# MCBSP1_DSP register map
Vendor: Texas Instruments
Peripheral module from a debugger description file (folder omap4430).
Registers are 32-bit, access per field, reset values left out (the file's numbers can be read two ways) unless marked. A register's access mark holds for its fields unless they carry their own. Offsets are as the file gives them; lines under a group give offsets from that group; [hi:lo] are bit positions; {n}, {i} and the like mark numbered series; 'fields as' and 'values as' point back to an identical list; <NAME> marks a mode.

## MCBSP1_DSP
0x00 MCBSPLP_DRR_REG ro — McBSPLP data receive register
  [31:0] DRR — Data receive register
0x08 MCBSPLP_DXR_REG wo — McBSPLP data transmit register
  [31:0] DXR — Data transmit register
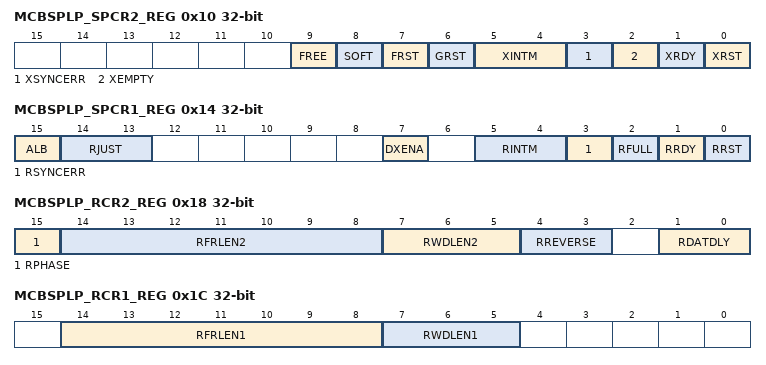
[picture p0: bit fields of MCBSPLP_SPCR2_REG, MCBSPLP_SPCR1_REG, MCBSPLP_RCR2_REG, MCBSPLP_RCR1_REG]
0x10 MCBSPLP_SPCR2_REG — McBSPLP serial port control register 2
  [9] FREE rw — Free Running Mode (When this bit is set, the module ignores the Msuspend input)
    0=Free running mode is disabled; 1=Free running mode is enabled
  [8] SOFT rw — Soft Bit
    0=SOFT mode is disabled: the module stops its activity immediately following MSuspend assertion; 1=SOFT mode is enabled: the module freezes its state after completion of the current operation when MSuspend is asserted
  [7] FRST rw — Frame-Sync Generator Reset
    0=Frame-sync logic is reset. Frame-sync signal FSG is not generated by the sample-rate generator; 1=Frame-sync signal FSG is generated after (FPER+1) number of CLKG clocks; that is, all frame counters are loaded with their programmed values
  [6] GRST rw — Sample-Rate Generator Reset
    0=SRG is reset; 1=SRG is pulled out of reset. CLKG is driven as per programmed value in SRG registers (SRGR[1,2])
  [5:4] XINTM rw — Transmit Interrupt Mode (legacy)
    0=XINT is driven by XRDY; 1=XINT generated by end-of-frame; 2=XINT generated by a new frame synchronization; 3=XINT generated by XSYNCERR
  [3] XSYNCERR rw — Transmit Synchronization Error (writing 0 to this bit clear the legacy transmit interrupt if asserted due to XSYNCERR condition)
    0=No synchronization error; 1=Synchronization error detected by McBSP
  [2] XEMPTY ro — Transmit Shift Register XSR Empty
    0=XEMPTY_0_r (XSR is empty); 1=XEMPTY_1_r (XSR is not empty)
  [1] XRDY ro — Transmitter ready
    0=XRDY_0_r (Transmitter is not ready.); 1=XRDY_1_r (Transmitter is ready for new data in DXR)
  [0] XRST rw — Transmitter reset. This resets and enables the transmitter.
    0=The serial port transmitter is disabled and in reset state; 1=The serial port transmitter is enabled
0x14 MCBSPLP_SPCR1_REG — McBSPLP serial port control register 1
  [15] ALB rw — Analog Loopback Mode
    0=Analog loopback mode disabled; 1=Analog loopback mode enabled
  [14:13] RJUST rw — Receive Sign-Extension and Justification Mode
    0=Right-justify and zero-fill MSBs in DRR; 1=Right-justify and sign-extend MSBs in DRR; 2=Left-justify and zero-fill LSBs in DRR
  [7] DXENA rw — DX Enabler
    0=DX enabler is off; 1=DX enabler is on
  [5:4] RINTM rw — Receive Interrupt Mode (legacy)
    0=RINT driven by RRDY (that is, end of word) and end of frame in A-bis mode; 1=RINT generated by end-of-block or end-of-frame in multichannel operation; 2=RINT generated by a new frame synchronization; 3=RINT generated by RSYNCERR
  [3] RSYNCERR rw — Receive Synchronization Error (writing 0 to this bit clear the legacy receive interrupt if asserted due to RSYNCERR condition)
    values as MCBSPLP_SPCR2_REG.XSYNCERR
  [2] RFULL ro — Receive Shift Register (RSR]) Full
    0=RFULL_0_r (DRR is not read, RB is full and RSR is also full with new word); 1=RFULL_1_r (RB is not in overrun condition)
  [1] RRDY ro — Receiver Ready
    0=RRDY_0_r (Receiver is not ready); 1=RRDY_1_r (Receiver is ready with data to be read from DRR)
  [0] RRST rw — Receiver reset. This resets and enables the receiver.
    0=The serial port receiver is disabled and in reset state; 1=The serial port receiver is enabled
0x18 MCBSPLP_RCR2_REG — McBSPLP receive control register 2
  [15] RPHASE rw — Receive Phases
    0=Single-phase frame; 1=Dual-phase frame
  [14:8] RFRLEN2 rw — Receive Frame Length 2 Single-phase frame selected: RFRLEN2=don't care Dual-phase frame selected: RFRLEN2=000 0000 - 1 word per second phase (other values are reserved)
  [7:5] RWDLEN2 rw — Receive Word Length 2
    0=8 bits; 1=12 bits; 2=16 bits; 3=20 bits; 4=24 bits; 5=32 bits
  [4:3] RREVERSE rw — Receive reverse mode.
    0=Data transfer starts with MSB first; 1=Data transfer starts with LSB first
  [1:0] RDATDLY rw — Receive Data Delay
    0=0-bit data delay; 1=1-bit data delay; 2=2-bit data delay
0x1C MCBSPLP_RCR1_REG — McBSPLP receive control register 1
  [14:8] RFRLEN1 rw — Receive Frame Length 1 Single-phase frame selected: RFRLEN1=000 0000 - 1 word per frame RFRLEN1=000 0001 - 2 words per frame RFRLEN1=111 1111 - 128 words per frame Dual-phase frame selected: RFRLEN1=000 0000 - 1 word per phase (other values are reserved)
  [7:5] RWDLEN1 rw — Receive Word Length 1
    values as MCBSPLP_RCR2_REG.RWDLEN2
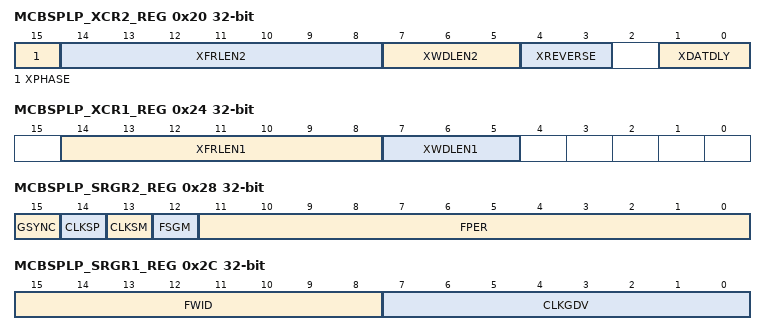
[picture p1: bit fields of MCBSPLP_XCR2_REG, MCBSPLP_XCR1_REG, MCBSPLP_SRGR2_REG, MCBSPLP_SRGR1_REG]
0x20 MCBSPLP_XCR2_REG — McBSPLP transmit control register 2
  [15] XPHASE rw — Transmit Phases
    0=Single-phase frame; 1=Dual-phase frame
  [14:8] XFRLEN2 rw — Transmit Frame Length 2 Single-phase frame selected: XFRLEN2=don't care Dual-phase frame selected: XFRLEN2=000 0000 - 1 word per second phase (other values are reserved)
  [7:5] XWDLEN2 rw — Transmit Word Length 2
    values as MCBSPLP_RCR2_REG.RWDLEN2
  [4:3] XREVERSE rw — Transmit reverse mode.
    values as MCBSPLP_RCR2_REG.RREVERSE
  [1:0] XDATDLY rw — Transmit Data Delay
    0=0-bit data delay; 1=1-bit data delay; 2=2-bit data delay
0x24 MCBSPLP_XCR1_REG — McBSPLP transmit control register 1
  [14:8] XFRLEN1 rw — Transmit Frame Length 1 Single-phase frame selected: XFRLEN1=000 0000 - 1 word per frame XFRLEN1=000 0001 - 2 words per frame XFRLEN1=111 1111 - 128 words per frame Dual-phase frame selected: XFRLEN1=000 0000 - 1 word per phase (other values are reserved)
  [7:5] XWDLEN1 rw — Transmit Word Length 1
    values as MCBSPLP_RCR2_REG.RWDLEN2
0x28 MCBSPLP_SRGR2_REG — McBSPLP sample rate generator register 2
  [15] GSYNC rw
    0=The SRG clock (CLKG) is free running; 1=The SRG clock (CLKG) is running. But CLKG is resynchronized and frame-sync signal (FSG) is generated only after detecting the receive frame-sync signal (FSR). Also, frame period, FPER, is a don't care because the period is dictated by the external frame-sync pulse.
  [14] CLKSP rw — CLKS Polarity Clock Edge Select Only used when the external clock CLKS drives the SRG clock (CLKSM=0).
    0=Rising edge of CLKG and FSG; 1=Falling edge of CLKG and FSG
  [13] CLKSM rw — McBSPLP Sample Rate Generator Clock Mode
    0=SCLKME=0: SRG clock derived from the CLKS pin. SCLKME=1: SRG clock derived from the CLKRI pin.; 1=SCLKME=0: SRG clock derived from the CPU clock. SCLKME=1: SRG clock derived from the CLKXI clock.
  [12] FSGM rw — Sample Rate Generator Transmit Frame-Synchronization Mode Used when FSXM=1 in the PCR.
    0=Transmit frame-sync signal (FSX) is generated when transmit buffer is not empty When FSGM=0, FPER and FWID are used to determine the frame-sync period and width (external FSX is gated by the buffer empty condition); 1=Transmit frame-sync signal driven by the SRG frame-sync signal, FSG
  [11:0] FPER rw — Frame Period. This field plus 1 determines when the next frame-sync signal becomes active. Range: 1 to 4096 CLKG periods
0x2C MCBSPLP_SRGR1_REG — McBSPLP sample rate generator register 1
  [15:8] FWID rw — Frame Width. This field plus 1 determines the width of the frame-sync pulse, FSG, during its active period. Range: 1 to 256 CLKG periods.
  [7:0] CLKGDV rw — Sample Rate Generator Clock Divider This value is used as the divide-down number to generate the required SRG clock frequency. Default value is 1.
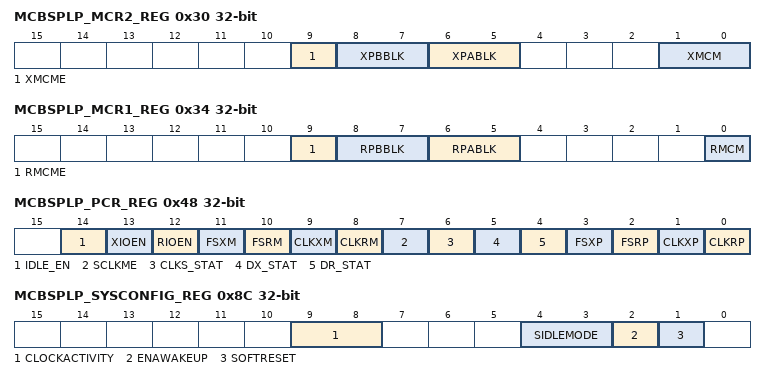
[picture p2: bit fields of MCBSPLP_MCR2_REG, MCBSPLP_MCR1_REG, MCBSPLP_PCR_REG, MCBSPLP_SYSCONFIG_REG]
0x30 MCBSPLP_MCR2_REG — McBSPLP multi channel register 2
  [9] XMCME rw
    0=2-partition mode: Only partitions A and B are used. You can control up to 32 channels in the transmit multichannel selection mode selected with the XMCM bits. If XMCM = 01b or 10b, assign 16 channels to partition A with the XPABLK bits. Assign 16 channels to partition B with the XPBBLK bits. If XMCM = 11b (for symmetric transmission and reception), assign 16 channels to receive partition A with the RPABLK bits. Assign 16 channels to receive partition B with the RPBBLK bits. You control the channels with the appropriate transmit channel enable registers: XCERA: Channels in partition A XCERB: Channels in partition B; 1=8-partition mode: All partitions (A through H) are used. You can control up to 128 channels in the transmit multichannel selection mode selected with the XMCM bits. You control the channels with the appropriate transmit channel enable registers: XCERA: Channels 0 through 15 XCERB: Channels 16 through 31 XCERC: Channels 32 through 47 XCERD: Channels 48 through 63 XCERE: Channels 64 through 79 XCERF: Channels 80 through 95 XCERG: Channels 96 through 111 XCERH: Channels 112 through 127
  [8:7] XPBBLK rw — Transmit Partition B Block (legacy)
    0=Block 1. Channel 16 to channel 31; 1=Block 3. Channel 48 to channel 63; 2=Block 5. Channel 80 to channel 95; 3=Block 7. Channel 112 to channel 127
  [6:5] XPABLK rw — Transmit Partition A Block (legacy)
    0=Block 0. Channel 0 to channel 15; 1=Block 2. Channel 32 to channel 47; 2=Block 4. Channel 64 to channel 79; 3=Block 6. Channel 96 to channel 111
  [1:0] XMCM rw — Transmit Multichannel Selection Enable
    0=All channels enabled without masking (DX is always driven during transmission of data); 1=All channels disabled and therefore masked by default. Required channels are selected by enabling XP(A/B)BLK and XCER(A/B) appropriately. Also, these selected channels are not masked and therefore DX is always driven.; 2=All channels enabled, but masked. Selected channels enabled via XP(A/B)BLK and XCER(A/B) are unmasked.; 3=All channels disabled and therefore masked by default. Required channels are selected by enabling RP(A/B)BLK and RCER(A/B) appropriately. Selected channels can be unmasked by RP(A/B)BLK and XCER(A/B). This mode is used for symetric transmit and receive operation.
0x34 MCBSPLP_MCR1_REG — McBSPLP multi channel register 1
  [9] RMCME rw — (legacy)
    0=2-partition mode. Only partitions A and B are used. You can control up to 32 channels in the receive multichannel selection mode (RMCM = 1). Assign 16 channels to partition A with the RPABLK bits. Assign 16 channels to partition B with the RPBBLK bits. You control the channels with the apropriate receive channel enable registers: RCERA: Channels in partition A RCERB: Channels in partition B; 1=8-partition mode: All partitions (A through H) are used. You can control up to 128 channels in the receive multichannel selection mode. You control the channels with the appropriate receive channel enable registers: RCERA: Channels 0 through 15 RCERB: Channels 16 through 31 RCERC: Channels 32 through 47 RCERD: Channels 48 through 63 RCERE: Channels 64 through 79 RCERF: Channels 80 through 95 RCERG: Channels 96 through 111 RCERH: Channels 112 through 127
  [8:7] RPBBLK rw — Receive Partition B Block (legacy)
    values as MCBSPLP_MCR2_REG.XPBBLK
  [6:5] RPABLK rw — Receive Partition A Block (legacy)
    values as MCBSPLP_MCR2_REG.XPABLK
  [0] RMCM rw — Receive Multichannel Selection Enable
    0=All 128 channels; 1=All channels disabled by default. Required channels are selected by enabling RP(A/B)BLK and RCER(A/B) appropriately
0x38 MCBSPLP_RCERA_REG — McBSPLP receive channel enable register partition A
  [15:0] RCERA rw — Receive Channel Enable RCERA n=0 Disables reception of n-th channel in an even-numbered block in partition A RCERA n=1 Enables reception of n-th channel in an even-numbered block in partition A
0x3C MCBSPLP_RCERB_REG — McBSPLP receive channel enable register partition B
  [15:0] RCERB rw — Receive Channel Enable RCERB n=0 Disables reception of n-th channel in a even-numbered block in partition B RCERB n=1 Enables reception of n-th channel in a even-numbered block in partition B
0x40 MCBSPLP_XCERA_REG — McBSPLP transmit channel enable register partition A
  [15:0] XCERA rw — Transmit Channel Enable XCERA n=0 Disables transmission of n-th channel in an event-numbered block in partition A XCERA n=1 Enables transmission of n-th channel in an event-numbered block in partition A
0x44 MCBSPLP_XCERB_REG — McBSPLP transmit channel enable register partition B
  [15:0] XCERB rw — Transmit Channel Enable XCERB n=0 Disables transmission of n-th channel in an even-numbered block in partition B XCERB n=1 Enables transmission of n-th channel in an even-numbered block in partition B
0x48 MCBSPLP_PCR_REG — McBSPLP pin control register
  [14] IDLE_EN rw — Idle enable. This bit allows stopping all the clocks in the MCBSPLP. (legacy)
    0=The McBSP is running; 1=The clocks in the McBSP are shut off when both IDLE_EN=1 and peripheral domain is in idle mode
  [13] XIOEN rw — Transmit General Purpose I/O Mode only when XRST=0 in SPCR[1,2] (legacy)
    0=DX, FSX and CLKX are configured as serial port pins and do not function as general-purpose I/Os; 1=DX pin is a general purpose output. FSX and CLKX are general purpose I/Os. These serial port pins do not perform serial port operation.
  [12] RIOEN rw — Receive General Purpose I/O Mode when RRST=0 in SPCR[1,2] (legacy)
    0=DR, FSR, CLKR and CLKS are configured as serial port pins and do not function as general-purpose I/Os; 1=DR and CLKS pins are general purpose inputs; FSR and CLKR are general purpose I/Os. These serial port pins do not perform serial port operation. The CLKS pin is affected by a combination of RRST and RIOEN signals of the receiver.
  [11] FSXM rw — Transmit Frame-Synchronization Mode
    0=Frame-sync signal derived from an external source; 1=Frame synchronization is determined by the SRG frame-sync mode bit FSGM in SRGR2
  [10] FSRM rw — Receive Frame-Synchronization Mode
    0=Frame-sync pulses generated by an external device. FSR is an input pin.; 1=Frame synchronization generated internally by SRG. FSR is an output pin except when GSYNC=1 in SRGR.
  [9] CLKXM rw — Transmitter Clock Mode
    0=Transmitter clock is driven by an external clock with CLKX as an input pin; 1=CLKX is an output pin and is driven by the internal sample rate generator
  [8] CLKRM rw — Receiver Clock Mode
    0=Case 1: Digital loopback mode not set (DLB=0) in SPCR1: Receive clock (CLKR) is an input driven by an externaal clock. Case 2: Digital loopback mode set (DLB=1) in SPCR1: Receive clock (not the CLKR pin) is driven by transmit clock (CLKX) which is based on the CLKXM bit in the PCR. CLKR pin is in high-impedance.; 1=Case 1: Digital loopback mode not set (DLB=0) in SPCR1: CLKR is an output pin and is driven by the internal SRG. Case 2: Digital loopback mode set (DLB=1) in SPCR1: CLKR is an output pin and is driven by the transmit clock. The transmit clock is derived based on the CLKRM bit in the PCR.
  [7] SCLKME rw — The frequency of CLKG is: CLKG frequency = (Input clock frequency) / (CLKGDV + 1) SCLKME is used in conjunction with the CLKSM bit to select the input clock:
    0=CLKSM = 0: Signal on CLKS pin CLKSM = 1: CPU clock; 1=CLKSM = 0: Signal on CLKR pin CLKSM = 1: Signal on CLKX pin
  [6] CLKS_STAT ro — CLKS pin status. Reflects value on CLKS pin when selected as a general purpose input. (legacy)
    0=CLKS_STAT_0_r (The signal on the CLKS pin is low); 1=CLKS_STAT_1_r (The signal on the CLKS pin is high)
  [5] DX_STAT rw — DX pin status. Reflects value driven on to DX pin when selected as a general purpose output. (legacy)
    0=Drive the signal on the DX pin low; 1=Drive the signal on the DX pin high
  [4] DR_STAT ro — DR pin status. Reflects value on DR pin when selected as a general purpose input. (legacy)
    0=DR_STAT_0_r (The signal on DR pin is low); 1=DR_STAT_1_r (The signal on DR pin is high)
  [3] FSXP rw — Transmit Frame-Synchronization Polarity
    0=Frame-sync pulse FSX is active high; 1=Frame-sync pulse FSX is active low
  [2] FSRP rw — Receive Frame-Synchronization Polarity
    0=Frame-sync pulse FSR is active high; 1=Frame-sync pulse FSR is active low
  [1] CLKXP rw — Transmit Clock Polarity
    0=Transmit data driven on rising edge of CLKX; 1=Transmit data driven on falling edge of CLKX
  [0] CLKRP rw — Receive Clock Polarity
    0=Receive data sampled on falling edge of CLKR; 1=Receive data sampled on rising edge of CLKR
0x4C MCBSPLP_RCERC_REG — McBSPLP receive channel enable register partition C
  [15:0] RCERC rw — Receive Channel Enable RCERC n=0 Disables reception of n-th channel in an even-numbered block in partition C RCERC n=1 Enables reception of n-th channel in an even-numbered block in partition C
0x50 MCBSPLP_RCERD_REG — McBSPLP receive channel enable register partition D
  [15:0] RCERD rw — Receive Channel Enable RCERD n=0 Disables reception of n-th channel in an even-numbered block in partition D RCERD n=1 Enables reception of n-th channel in an even-numbered block in partition D
0x54 MCBSPLP_XCERC_REG — McBSPLP transmit channel enable register partition C
  [15:0] XCERC rw — Transmit Channel Enable XCERC n=0 Disables transmission of n-th channel in an event-numbered block in partition C XCERC n=1 Enables transmission of n-th channel in an event-numbered block in partition C
0x58 MCBSPLP_XCERD_REG — McBSPLP transmit channel enable register partition D
  [15:0] XCERD rw — Transmit Channel Enable XCERD n=0 Disables transmission of n-th channel in an even-numbered block in partition D XCERD n=1 Enables transmission of n-th channel in an even-numbered block in partition D
0x5C MCBSPLP_RCERE_REG — McBSPLP receive channel enable register partition E
  [15:0] RCERE rw — Receive Channel Enable RCERE n=0 Disables reception of n-th channel in an even-numbered block in partition E RCERE n=1 Enables reception of n-th channel in an even-numbered block in partition E
0x60 MCBSPLP_RCERF_REG — McBSPLP receive channel enable register partition F
  [15:0] RCERF rw — Receive Channel Enable RCERF n=0 Disables reception of n-th channel in an even-numbered block in partition F RCERF n=1 Enables reception of n-th channel in an even-numbered block in partition F
0x64 MCBSPLP_XCERE_REG — McBSPLP transmit channel enable register partition E
  [15:0] XCERE rw — Transmit Channel Enable XCERE n=0 Disables transmission of n-th channel in an event-numbered block in partition E XCERE n=1 Enables transmission of n-th channel in an event-numbered block in partition E
0x68 MCBSPLP_XCERF_REG — McBSPLP transmit channel enable register partition F
  [15:0] XCERF rw — Transmit Channel Enable XCERF n=0 Disables transmission of n-th channel in an even-numbered block in partition F XCERF n=1 Enables transmission of n-th channel in an even-numbered block in partition F
0x6C MCBSPLP_RCERG_REG — McBSPLP receive channel enable register partition G
  [15:0] RCERG rw — Receive Channel Enable RCERG n=0 Disables reception of n-th channel in an even-numbered block in partition G RCERG n=1 Enables reception of n-th channel in an even-numbered block in partition G
0x70 MCBSPLP_RCERH_REG — McBSPLP receive channel enable register partition H
  [15:0] RCERH rw — Receive Channel Enable RCERH n=0 Disables reception of n-th channel in an even-numbered block in partition H RCERH n=1 Enables reception of n-th channel in an even-numbered block in partition H
0x74 MCBSPLP_XCERG_REG — McBSPLP transmit channel enable register partition G
  [15:0] XCERG rw — Transmit Channel Enable XCERG n=0 Disables transmission of n-th channel in an event-numbered block in partition G XCERG n=1 Enables transmission of n-th channel in an event-numbered block in partition G
0x78 MCBSPLP_XCERH_REG — McBSPLP transmit channel enable register partition H
  [15:0] XCERH rw — Transmit Channel Enable XCERH n=0 Disables transmission of n-th channel in an even-numbered block in partition H XCERH n=1 Enables transmission of n-th channel in an even-numbered block in partition H
0x7C MCBSPLP_REV_REG ro — MCBSPLP Revision number register
  [7:0] REV — Revision number
0x80 MCBSPLP_RINTCLR_REG rw — McBSPLP receive interrupt clear
  [31:0] RINTCLR — Read from this register will clear the IRQ generated by receive end-of-frame indication or MCBSPLP.FSR detection. Write to this register has no effect. (legacy)
0x84 MCBSPLP_XINTCLR_REG rw — McBSPLP transmit interrupt clear (legacy)
  [31:0] XINTCLR — Read from this register will clear the IRQ generated by transmit end-of-frame indication or MCBSPLP.FSX detection. Write to this register has no effect.
0x88 MCBSPLP_ROVFLCLR_REG rw — McBSPLP receive overflow interrupt clear
  [31:0] ROVFLCLR — Read from this register will clear the IRQ generated by the receive overflow condition. Write to this register has no effect.
0x8C MCBSPLP_SYSCONFIG_REG — McBSPLP System Configuration register
  [9:8] CLOCKACTIVITY rw
    0=The MCBSPi_ICLK clock can be switched off. The PRCM functional clock can be switched off.; 1=The MCBSPi_ICLK clock must be maintained during wakeup. The PRCM functional clock can be switched off.; 2=The MCBSPi_ICLK clock can be switched off. The PRCM functional clock must be maintained during wakeup.; 3=The MCBSPi_ICLK clock must be maintained during wakeup. The PRCM functional clock must be maintained during wakeup
  [4:3] SIDLEMODE rw — Slave interface power management, req/ack control:
    0=Force-idle. An idle request is acknowledged unconditionally.; 1=No-idle. An idle request is never acknowledged.; 2=Smart-idle. Acknowledgement to an idle request is given based on the internal activity of the module
  [2] ENAWAKEUP rw — WakeUp feature control:
    0=WakeUp is disabled; 1=WakeUp capability is enabled
  [1] SOFTRESET rw — McBSPLP global software reset
    0=NO soft reset; 1=Soft reset triggered
0x90 MCBSPLP_THRSH2_REG — McBSPLP transmit buffer threshold (DMA or IRQ trigger)
  [6:0] XTHRESHOLD rw — Transmit buffer threshold value. The DMA request (if enabled) of interrupt assertion (if enabled) will be triggered if the number of free locations inside transmit buffer are above or equal to the XTHRESHOLD value + 1. Also, this value (XTHRESHOLD value + 1) indicates the number of words transferred during a transmit data DMA request, if transmit DMA is enabled
0x94 MCBSPLP_THRSH1_REG — McBSPLP receive buffer threshold (DMA or IRQ trigger)
  [6:0] RTHRESHOLD rw — Receive buffer threshold value. The DMA request (if enabled) of interrupt assertion (if enabled) will be triggered if the number of occupied locations inside receive buffer are above or equal to the RTHRESHOLD value + 1. Also, this value (RTHRESHOLD value + 1) indicates the number of words transferred during a receive data DMA request, if receive DMA is enabled.
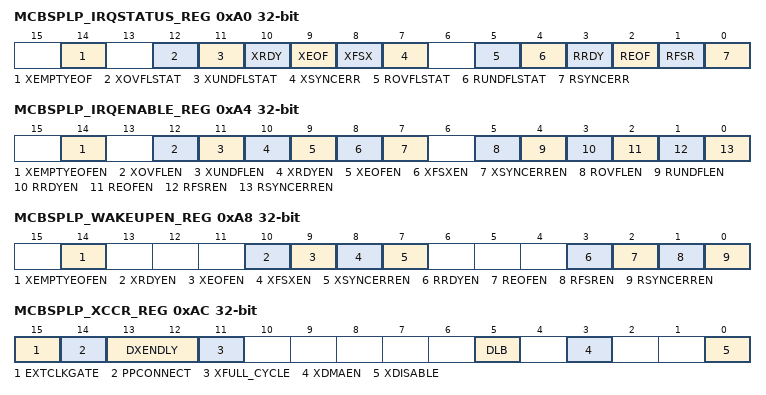
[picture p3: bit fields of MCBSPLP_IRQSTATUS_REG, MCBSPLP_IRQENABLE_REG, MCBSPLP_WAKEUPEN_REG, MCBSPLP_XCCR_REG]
0xA0 MCBSPLP_IRQSTATUS_REG — McBSPLP Interrupt Status register (interconnect compliant IRQ line)
  [14] XEMPTYEOF rw — Transmit Buffer Empty at end of frame (XEMPTYEOF is set to 1 when a complete frame was transmitted and the transmit buffer is empty).
    0=XEMPTYEOF is NOT set to when a complete frame was transmitted and the transmit buffer is empty; 1=XEMPTYEOF is set to 1 when a complete frame was transmitted and the transmit buffer is empty. Writing 1 to this bit clears the bit.
  [12] XOVFLSTAT rw — Transmit Buffer Overflow (XOVFLSTAT bit is set to 1 when transmit buffer overflow; the data which is written while overflow condition is discarded). Writing 1 to this bit clears the bit.
    0=Transmit buffer NOT overflow; 1=Transmit buffer overflow; Writing 1 to this bit clears the bit
  [11] XUNDFLSTAT rw — Transmit Buffer Underflow (XUNDFLSTAT bit is set to 1 when the transmit data buffer is empty new data is required to be transmitted). Writing 1 to this bit clears the bit.
    0=the transmit data buffer is NOT empty new data is required to be transmitted; 1=the transmit data buffer is empty new data is required to be transmitted. Writing 1 to this bit clears the bit.
  [10] XRDY rw — Transmit Buffer Threshold Reached (XRDY bit is set to 1 when the transmit buffer free locations are equal or above the THRSH2_REG value). Writing 1 to this bit clears the bit.
    0=Transmit buffer occupied locations are below the THRSH2_REG value); 1=Transmit buffer occupied locations are equal or above the THRSH2_REG value). Writing 1 to this bit clears the bit.
  [9] XEOF rw — Transmit End Of Frame (XEOF is set to 1 when a complete frame was transmitted). Writing 1 to this bit clears the bit.
    0=complete frame was NOT transmitted; 1=complete frame was transmitted; Writing 1 to this bit clears the bit
  [8] XFSX rw — Transmit Frame Synchronization (XFSX bit is set to 1 when a new transmit frame synchronization is asserted). Writing 1 to this bit clears the bit.
    0=new transmit frame synchronization is NOT asserted; 1=new transmit frame synchronization is asserted; Writing 1 to this bit clears the bit
  [7] XSYNCERR rw — Transmit Frame Synchronization Error (XSYNCERR is set to 1 when a transmit frame-sync error is detected). Writing 1 to this bit clears the bit.
    0=Transmit frame-sync error is NOT detected; 1=Transmit frame-sync error is detected. Writing 1 to this bit clears the bit.
  [5] ROVFLSTAT rw — Receive Buffer Overflow (ROVFLSTAT bit is set to 1 when receive buffer overflow; the data which is written while overflow condition is discarded). Writing 1 to this bit clears the bit.
    0=receive buffer NOT overflow; 1=receive buffer overflow; Writing 1 to this bit clears the bit
  [4] RUNDFLSTAT rw — Receive Buffer Underflow (RUNDFLSTAT bit is set to 1 when read operation is performed to the receive data register while receive buffer is empty; data read while underflow condition is undefined). Writing 1 to this bit clears the bit.
    0=read operation is performed to the receive data register while receive buffer is NOT empty; 1=read operation is performed to the receive data register while receive buffer is empty; Writing 1 to this bit clears the bit
  [3] RRDY rw — Receive Buffer Threshold Reached (RRDY bit is set to 1 when the receive buffer occupied locations are equal or above the THRSH1_REG value). Writing 1 to this bit clears the bit.
    0=receive buffer occupied locations are below the THRSH1_REG value); 1=receive buffer occupied locations are equal or above the THRSH1_REG value). Writing 1 to this bit clears the bit.
  [2] REOF rw — Receive End Of Frame (REOF is set to 1 when a complete frame was received). Writing 1 to this bit clears the bit.
    0=complete frame was NOT received; 1=complete frame was received; Writing 1 to this bit clears the bit
  [1] RFSR rw — Receive Frame Synchronization (RFSR bit is set to 1 when a new receive frame synchronization is asserted). Writing 1 to this bit clears the bit.
    0=new receive frame synchronization is NOT asserted; 1=new receive frame synchronization is asserted; Writing 1 to this bit clears the bit
  [0] RSYNCERR rw — Receive Frame Synchronization Error (RSYNCERR is set to 1 when a receive frame-sync error is detected). Writing 1 to this bit clears the bit.
    0=Receive frame-synchronization error is NOT detected; 1=Receive frame-synchronization error is detected. Writing 1 to this bit clears the bit.
0xA4 MCBSPLP_IRQENABLE_REG — McBSPLP Interrupt Enable register (interconnect compliant IRQ line)
  [14] XEMPTYEOFEN rw — Transmit buffer empty at end of frame enable bit.
    0=Transmit Buffer Empty at End Of Frame NOT enabled; 1=Transmit Buffer Empty at End Of Frame enabled
  [12] XOVFLEN rw — Transmit Buffer Overflow enable bit.
    0=Transmit Buffer Overflow NOT enabled; 1=Transmit Buffer Overflow enabled
  [11] XUNDFLEN rw — Transmit Buffer Underflow enable bit.
    0=Transmit Buffer Underflow NOT enabled; 1=Transmit Buffer Underflow enabled
  [10] XRDYEN rw — Transmit Buffer Threshold Reached enable bit.
    0=Transmit Buffer Threshold Reached NOT enabled; 1=Transmit Buffer Threshold Reached enabled
  [9] XEOFEN rw — Transmit End Of Frame enable bit.
    0=Transmit End Of Frame NOT enabled; 1=Transmit End Of Frame enabled
  [8] XFSXEN rw — Transmit Frame Synchronization enable bit.
    0=Transmit Frame Synchronization NOT enabled; 1=Transmit Frame Synchronization enabled
  [7] XSYNCERREN rw — Transmit Frame Synchronization Error enable bit.
    0=Transmit Frame Synchronization Error NOT enabled; 1=Transmit Frame Synchronization Error enabled
  [5] ROVFLEN rw — Receive Buffer Overflow enable bit.
    0=Receive Buffer Overflow NOT enabled; 1=Receive Buffer Overflow enabled
  [4] RUNDFLEN rw — Receive Buffer Underflow enable bit.
    0=Receive Buffer Underflow NOT enabled; 1=Receive Buffer Underflow enabled
  [3] RRDYEN rw — Receive Buffer Threshold enable bit.
    0=Receive Buffer Threshold NOT enabled; 1=Receive Buffer Threshold enabled
  [2] REOFEN rw — Receive End Of Frame enable bit.
    0=Receive End Of Frame NOT enabled; 1=Receive End Of Frame enabled
  [1] RFSREN rw — Receive Frame Synchronization enable bit. RW
    0=Receive Frame Synchronization NOT enabled; 1=Receive Frame Synchronization enabled
  [0] RSYNCERREN rw — Receive Frame Synchronization Error enable bit.
    0=Receive Frame Synchronization Error NOT enabled; 1=Receive Frame Synchronization Error enabled
0xA8 MCBSPLP_WAKEUPEN_REG — McBSPLP Wakeup Enable register
  [14] XEMPTYEOFEN rw — Transmit Buffer Empty at End Of Frame enable bit.
    0=Transmit Buffer Empty at End Of Frame WK enable is NOT active; 1=Transmit Buffer Empty at End Of Frame WK enable is active
  [10] XRDYEN rw — Transmit Buffer Threshold Reached WK enable bit.
    0=Transmit Buffer Threshold WK enable is NOT active; 1=Transmit Buffer Threshold WK enable is active
  [9] XEOFEN rw — Transmit End Of Frame WK enable bit.
    0=Transmit End Of Frame WK enable is NOT active; 1=Transmit End Of Frame WK enable is active
  [8] XFSXEN rw — Transmit Frame Synchronization WK enable bit.
    0=Transmit Frame Synchronization WK enable is NOT active; 1=Transmit Frame Synchronization WK enable is active
  [7] XSYNCERREN rw — Transmit Frame Synchronization Error WK enable bit.
    0=Transmit Frame Synchronization Error WK enable is NOT active; 1=Transmit Frame Synchronization Error WK enable is active
  [3] RRDYEN rw — Receive Buffer Threshold wakeup enable bit.
    0=Receive Buffer Threshold WK enable is NOT active; 1=Receive Buffer Threshold WK enable is active
  [2] REOFEN rw — Receive End Of Frame WK enable bit.
    0=Receive End Of Frame WK enable is NOT active; 1=Receive End Of Frame WK enable is active
  [1] RFSREN rw — Receive Frame Synchronization WK enable bit.
    0=Receive Frame Synchronization WK enable is NOT active; 1=Receive Frame Synchronization WK enable is active
  [0] RSYNCERREN rw — Receive Frame Synchronization Error WK enable bit.
    0=Receive Frame Synchronization Error WK enable is NOT active; 1=Receive Frame Synchronization Error WK enable is active
0xAC MCBSPLP_XCCR_REG — McBSPLP transmit configuration control register
  [15] EXTCLKGATE rw — External clock gating enable (CLKX and FSX master only). When this bit is set and the transmit clock and FSX are set as output, the CLKX is enabled when FSX is active plus 3 clock cycles after (clock is provided for FWID + 4 clock cycles, assuming that the FSX width, active, is FWID + 1 clock cycles); outside this window the external transmit clock is gated. The receive use the same gated transmit clock and transmit frame synchronization signals regardless of the CLKRM/FSRM settings. When using this mode the frame synchronization signal must be active during reception of the entire frame (FWID must be programmed accordingly) to ensure the proper receive process, which requires at least 3 cycles after the frame complete to transfer the data into the receive buffer.
    0=External clock gating disabled; 1=External clock gating enable
  [14] PPCONNECT rw — Pair to pair connection. When set the DXENO pin is always set to 0 regardless of the frame boundary, setting the tree state buffer as output
    0=Pair to pair connection. When set the DXENO pin is always set to 0 regardless of the frame boundary, setting the tree state buffer as output; 1=Pair to pair connection. When set the DXENO pin is always set to 0 regardless of the frame boundary, setting the tree state buffer as output
  [13:12] DXENDLY rw — When DXENA bit in SPCR1 is set to 1 this field selects the added delay as follow:
    0=80 ps; 1=160 ps (default); 2=240 ps; 3=320 ps
  [11] XFULL_CYCLE rw — Transmit full-cycle mode select.
    0=McBSPLP operates in transmit half-cycle mode (transmit frame synchronization is sampled by the opposite edge of the clock used to drive transmit data); 1=McBSPLP operates in transmit full-cycle mode (transmit frame synchronization is sampled by the same edge of the clock used to drive transmit data)
  [5] DLB rw — Digital Loop-Back
    0=No DLB; 1=DLB
  [3] XDMAEN rw — Transmit DMA Enable bit. When set to 0 this bit will gate the external transmit DMA request, without resetting the DMA state machine. It is recommended to change this bit value only during transmit reset.
    0=When set to 0 this bit will gate the external transmit DMA request,; 1=When set to 1 this bit will NOT gate the external transmit DMA request,
  [0] XDISABLE rw — Transmit Disable bit. When this bit is set the transmit process will stop at the next frame boundary.
    0=The transmit process will NOT stop at the next frame boundary; 1=The transmit process will stop at the next frame boundary
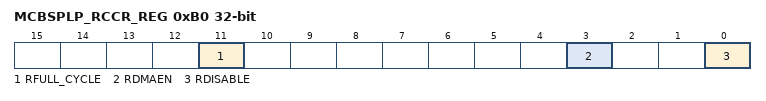
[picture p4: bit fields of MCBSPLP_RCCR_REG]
0xB0 MCBSPLP_RCCR_REG — McBSPLP receive configuration control register
  [11] RFULL_CYCLE rw — Receive full-cycle mode select.
    0=McBSPLP operates in receive half-cycle mode (receive frame synchronization is sampled by the opposite edge of the clock used to sample receive data); 1=McBSPLP operates in receive full-cycle mode (receive frame synchronization is sampled by the same edge of the clock used to sample receive data)
  [3] RDMAEN rw — Receive DMA Enable bit. When set to 0 this bit will gate the external transmit DMA request, without resetting the DMA state machine. It is recommended to change this bit value only during receive reset.
    0=When set to 0 this bit will gate the external transmit DMA request; 1=When set to 1 this bit will NOT gate the external transmit DMA request
  [0] RDISABLE rw — Receive Disable bit. When this bit is set the receive process will stop at the next frame boundary.
    0=the receive process will NOT stop at the next frame boundary; 1=When this bit is set the receive process will stop at the next frame boundary
0xB4 MCBSPLP_XBUFFSTAT_REG ro — McBSPLP transmit buffer status
  [7:0] XBUFFSTAT — Transmit Buffer Status (indicates the number of free locations inside transmit buffer). The XBUFFSTAT value reflects the buffer status on the interface clock domain and it can be smaller than the number of free locations which are seen by the transmit state machine.
0xB8 MCBSPLP_RBUFFSTAT_REG ro — McBSPLP receive buffer status
  [7:0] RBUFFSTAT — Receive Buffer Status (indicates the number of occupied locations inside receive buffer). The RBUFFSTAT value reflects the buffer status on the interface clock domain and it can be smaller than the real number of the occupied locations which are seen by the receive state machine.
